AUTOSAR XML (schema 4-3-1)
standard types defined: Double, SInt8, float64, sint8
package /pkg/swc
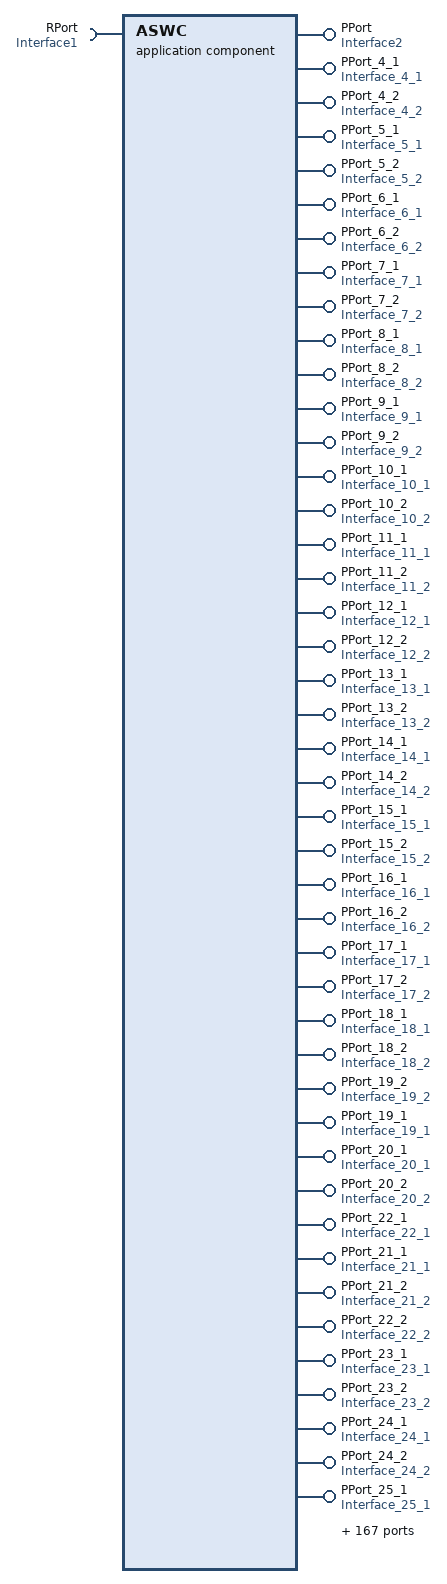
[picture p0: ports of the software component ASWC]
  application sw component type ASWC
    require port RPort: required-interface=Interface1
      required-com-specs:
        {data-element=Interface1/DE1, alive-timeout=60, init-value=constant-reference={short-label=DefaultInitValue_Double, constant=DefaultInitValue_Double}}
        {data-element=Interface1/DE2, alive-timeout=60, init-value=constant-reference={short-label=DefaultInitValu_036fab392deee624, constant=DefaultInitValu_036fab392deee624}}
    211 x provide port:
      PPort: provided-interface=Interface2
        provided-com-specs:
          {data-element=Interface2/DE1, init-value=constant-reference={short-label=DefaultInitValue_SInt8, constant=DefaultInitValue_SInt8}}
          {data-element=Interface2/DE2, init-value=constant-reference={short-label=DefaultInitValue_SInt8, constant=DefaultInitValue_SInt8}}
          {data-element=DE3, init-value=constant-reference={short-label=DefaultInitValu_33c01c7d02936bc6, constant=DefaultInitValu_33c01c7d02936bc6}}
          {data-element=DE4, init-value=constant-reference={short-label=DefaultInitValue_Double, constant=DefaultInitValue_Double}}
      PPort_4_1: nonqueued-sender-com-spec{data-element=DE1, init-value=[0, 0]}, provided-interface=Interface_4_1
      PPort_4_2: nonqueued-sender-com-spec{data-element=DE1, init-value=[0, 0]}, provided-interface=Interface_4_2
      PPort_5_1: nonqueued-sender-com-spec{data-element=DE1, init-value=[0, 0]}, provided-interface=Interface_5_1
      PPort_5_2: nonqueued-sender-com-spec{data-element=DE1, init-value=[0, 0]}, provided-interface=Interface_5_2
      PPort_6_1: nonqueued-sender-com-spec{data-element=DE1, init-value=[0, 0]}, provided-interface=Interface_6_1
      PPort_6_2: nonqueued-sender-com-spec{data-element=DE1, init-value=[0, 0]}, provided-interface=Interface_6_2
      PPort_7_1: nonqueued-sender-com-spec{data-element=DE1, init-value=[0, 0]}, provided-interface=Interface_7_1
      PPort_7_2: nonqueued-sender-com-spec{data-element=DE1, init-value=[0, 0]}, provided-interface=Interface_7_2
      PPort_8_1: nonqueued-sender-com-spec{data-element=DE1, init-value=[0, 0]}, provided-interface=Interface_8_1
      PPort_8_2: nonqueued-sender-com-spec{data-element=DE1, init-value=[0, 0]}, provided-interface=Interface_8_2
      PPort_9_1: nonqueued-sender-com-spec{data-element=DE1, init-value=[0, 0]}, provided-interface=Interface_9_1
      PPort_9_2: nonqueued-sender-com-spec{data-element=DE1, init-value=[0, 0]}, provided-interface=Interface_9_2
      PPort_10_1: nonqueued-sender-com-spec{data-element=DE1, init-value=[0, 0]}, provided-interface=Interface_10_1
      PPort_10_2: nonqueued-sender-com-spec{data-element=DE1, init-value=[0, 0]}, provided-interface=Interface_10_2
      PPort_11_1: nonqueued-sender-com-spec{data-element=DE1, init-value=[0, 0]}, provided-interface=Interface_11_1
      PPort_11_2: nonqueued-sender-com-spec{data-element=DE1, init-value=[0, 0]}, provided-interface=Interface_11_2
      PPort_12_1: nonqueued-sender-com-spec{data-element=DE1, init-value=[0, 0]}, provided-interface=Interface_12_1
      PPort_12_2: nonqueued-sender-com-spec{data-element=DE1, init-value=[0, 0]}, provided-interface=Interface_12_2
      PPort_13_1: nonqueued-sender-com-spec{data-element=DE1, init-value=[0, 0]}, provided-interface=Interface_13_1
      PPort_13_2: nonqueued-sender-com-spec{data-element=DE1, init-value=[0, 0]}, provided-interface=Interface_13_2
      PPort_14_1: nonqueued-sender-com-spec{data-element=DE1, init-value=[0, 0]}, provided-interface=Interface_14_1
      PPort_14_2: nonqueued-sender-com-spec{data-element=DE1, init-value=[0, 0]}, provided-interface=Interface_14_2
      PPort_15_1: nonqueued-sender-com-spec{data-element=DE1, init-value=[0, 0]}, provided-interface=Interface_15_1
      PPort_15_2: nonqueued-sender-com-spec{data-element=DE1, init-value=[0, 0]}, provided-interface=Interface_15_2
      PPort_16_1: nonqueued-sender-com-spec{data-element=DE1, init-value=[0, 0]}, provided-interface=Interface_16_1
      PPort_16_2: nonqueued-sender-com-spec{data-element=DE1, init-value=[0, 0]}, provided-interface=Interface_16_2
      PPort_17_1: nonqueued-sender-com-spec{data-element=DE1, init-value=[0, 0]}, provided-interface=Interface_17_1
      PPort_17_2: nonqueued-sender-com-spec{data-element=DE1, init-value=[0, 0]}, provided-interface=Interface_17_2
      PPort_18_1: nonqueued-sender-com-spec{data-element=DE1, init-value=[0, 0]}, provided-interface=Interface_18_1
      PPort_18_2: nonqueued-sender-com-spec{data-element=DE1, init-value=[0, 0]}, provided-interface=Interface_18_2
      PPort_19_2: nonqueued-sender-com-spec{data-element=DE1, init-value=[0, 0]}, provided-interface=Interface_19_2
      PPort_19_1: nonqueued-sender-com-spec{data-element=DE1, init-value=[0, 0]}, provided-interface=Interface_19_1
      PPort_20_1: nonqueued-sender-com-spec{data-element=DE1, init-value=[0, 0]}, provided-interface=Interface_20_1
      PPort_20_2: nonqueued-sender-com-spec{data-element=DE1, init-value=[0, 0]}, provided-interface=Interface_20_2
      PPort_22_1: nonqueued-sender-com-spec{data-element=DE1, init-value=[0, 0]}, provided-interface=Interface_22_1
      PPort_21_1: nonqueued-sender-com-spec{data-element=DE1, init-value=[0, 0]}, provided-interface=Interface_21_1
      PPort_21_2: nonqueued-sender-com-spec{data-element=DE1, init-value=[0, 0]}, provided-interface=Interface_21_2
      PPort_22_2: nonqueued-sender-com-spec{data-element=DE1, init-value=[0, 0]}, provided-interface=Interface_22_2
      PPort_23_1: nonqueued-sender-com-spec{data-element=DE1, init-value=[0, 0]}, provided-interface=Interface_23_1
      PPort_23_2: nonqueued-sender-com-spec{data-element=DE1, init-value=[0, 0]}, provided-interface=Interface_23_2
      PPort_24_1: nonqueued-sender-com-spec{data-element=DE1, init-value=[0, 0]}, provided-interface=Interface_24_1
      PPort_24_2: nonqueued-sender-com-spec{data-element=DE1, init-value=[0, 0]}, provided-interface=Interface_24_2
      PPort_25_1: nonqueued-sender-com-spec{data-element=DE1, init-value=[0, 0]}, provided-interface=Interface_25_1
      PPort_25_2: nonqueued-sender-com-spec{data-element=DE1, init-value=[0, 0]}, provided-interface=Interface_25_2
      PPort_26_1: nonqueued-sender-com-spec{data-element=DE1, init-value=[0, 0]}, provided-interface=Interface_26_1
      PPort_26_2: nonqueued-sender-com-spec{data-element=DE1, init-value=[0, 0]}, provided-interface=Interface_26_2
      PPort_27_1: nonqueued-sender-com-spec{data-element=DE1, init-value=[0, 0]}, provided-interface=Interface_27_1
      PPort_27_2: nonqueued-sender-com-spec{data-element=DE1, init-value=[0, 0]}, provided-interface=Interface_27_2
      PPort_28_1: nonqueued-sender-com-spec{data-element=DE1, init-value=[0, 0]}, provided-interface=Interface_28_1
      PPort_28_2: nonqueued-sender-com-spec{data-element=DE1, init-value=[0, 0]}, provided-interface=Interface_28_2
      PPort_29_1: nonqueued-sender-com-spec{data-element=DE1, init-value=[0, 0]}, provided-interface=Interface_29_1
      PPort_29_2: nonqueued-sender-com-spec{data-element=DE1, init-value=[0, 0]}, provided-interface=Interface_29_2
      PPort_30_1: nonqueued-sender-com-spec{data-element=DE1, init-value=[0, 0]}, provided-interface=Interface_30_1
      PPort_30_2: nonqueued-sender-com-spec{data-element=DE1, init-value=[0, 0]}, provided-interface=Interface_30_2
      PPort_31_1: nonqueued-sender-com-spec{data-element=DE1, init-value=[0, 0]}, provided-interface=Interface_31_1
      PPort_31_2: nonqueued-sender-com-spec{data-element=DE1, init-value=[0, 0]}, provided-interface=Interface_31_2
      PPort_32_1: nonqueued-sender-com-spec{data-element=DE1, init-value=[0, 0]}, provided-interface=Interface_32_1
      PPort_32_2: nonqueued-sender-com-spec{data-element=DE1, init-value=[0, 0]}, provided-interface=Interface_32_2
      PPort_33_1: nonqueued-sender-com-spec{data-element=DE1, init-value=[0, 0]}, provided-interface=Interface_33_1
      PPort_33_2: nonqueued-sender-com-spec{data-element=DE1, init-value=[0, 0]}, provided-interface=Interface_33_2
      PPort_34_1: nonqueued-sender-com-spec{data-element=DE1, init-value=[0, 0]}, provided-interface=Interface_34_1
      PPort_34_2: nonqueued-sender-com-spec{data-element=DE1, init-value=[0, 0]}, provided-interface=Interface_34_2
      PPort_35_1: nonqueued-sender-com-spec{data-element=DE1, init-value=[0, 0]}, provided-interface=Interface_35_1
      PPort_35_2: nonqueued-sender-com-spec{data-element=DE1, init-value=[0, 0]}, provided-interface=Interface_35_2
      PPort_36_1: nonqueued-sender-com-spec{data-element=DE1, init-value=[0, 0]}, provided-interface=Interface_36_1
      PPort_36_2: nonqueued-sender-com-spec{data-element=DE1, init-value=[0, 0]}, provided-interface=Interface_36_2
      PPort_37_1: nonqueued-sender-com-spec{data-element=DE1, init-value=[0, 0]}, provided-interface=Interface_37_1
      PPort_37_2: nonqueued-sender-com-spec{data-element=DE1, init-value=[0, 0]}, provided-interface=Interface_37_2
      PPort_38_1: nonqueued-sender-com-spec{data-element=DE1, init-value=[0, 0]}, provided-interface=Interface_38_1
      PPort_38_2: nonqueued-sender-com-spec{data-element=DE1, init-value=[0, 0]}, provided-interface=Interface_38_2
      PPort_39_1: nonqueued-sender-com-spec{data-element=DE1, init-value=[0, 0]}, provided-interface=Interface_39_1
      PPort_39_2: nonqueued-sender-com-spec{data-element=DE1, init-value=[0, 0]}, provided-interface=Interface_39_2
      PPort_40_1: nonqueued-sender-com-spec{data-element=DE1, init-value=[0, 0]}, provided-interface=Interface_40_1
      PPort_40_2: nonqueued-sender-com-spec{data-element=DE1, init-value=[0, 0]}, provided-interface=Interface_42_2
      PPort_41_1: nonqueued-sender-com-spec{data-element=DE1, init-value=[0, 0]}, provided-interface=Interface_41_1
      PPort_41_2: nonqueued-sender-com-spec{data-element=DE1, init-value=[0, 0]}, provided-interface=Interface_41_2
      PPort_42_1: nonqueued-sender-com-spec{data-element=DE1, init-value=[0, 0]}, provided-interface=Interface_42_1
      PPort_42_2: nonqueued-sender-com-spec{data-element=DE1, init-value=[0, 0]}, provided-interface=Interface_42_2
      PPort_43_1: nonqueued-sender-com-spec{data-element=DE1, init-value=[0, 0]}, provided-interface=Interface_43_1
      PPort_43_2: nonqueued-sender-com-spec{data-element=DE1, init-value=[0, 0]}, provided-interface=Interface_43_2
      PPort_44_1: nonqueued-sender-com-spec{data-element=DE1, init-value=[0, 0]}, provided-interface=Interface_44_1
      PPort_44_2: nonqueued-sender-com-spec{data-element=DE1, init-value=[0, 0]}, provided-interface=Interface_44_2
      PPort_45_1: nonqueued-sender-com-spec{data-element=DE1, init-value=[0, 0]}, provided-interface=Interface_45_1
      PPort_45_2: nonqueued-sender-com-spec{data-element=DE1, init-value=[0, 0]}, provided-interface=Interface_45_2
      PPort_46_1: nonqueued-sender-com-spec{data-element=DE1, init-value=[0, 0]}, provided-interface=Interface_46_1
      PPort_46_2: nonqueued-sender-com-spec{data-element=DE1, init-value=[0, 0]}, provided-interface=Interface_46_2
      PPort_47_1: nonqueued-sender-com-spec{data-element=DE1, init-value=[0, 0]}, provided-interface=Interface_47_1
      PPort_47_2: nonqueued-sender-com-spec{data-element=DE1, init-value=[0, 0]}, provided-interface=Interface_47_2
      PPort_48_1: nonqueued-sender-com-spec{data-element=DE1, init-value=[0, 0]}, provided-interface=Interface_48_1
      PPort_48_2: nonqueued-sender-com-spec{data-element=DE1, init-value=[0, 0]}, provided-interface=Interface_48_2
      PPort_49_1: nonqueued-sender-com-spec{data-element=DE1, init-value=[0, 0]}, provided-interface=Interface_49_1
      PPort_49_2: nonqueued-sender-com-spec{data-element=DE1, init-value=[0, 0]}, provided-interface=Interface_49_2
      PPort_50_1: nonqueued-sender-com-spec{data-element=DE1, init-value=[0, 0]}, provided-interface=Interface_50_1
      PPort_50_2: nonqueued-sender-com-spec{data-element=DE1, init-value=[0, 0]}, provided-interface=Interface_50_2
      PPort_51_1: nonqueued-sender-com-spec{data-element=DE1, init-value=[0, 0]}, provided-interface=Interface_51_1
      PPort_51_2: nonqueued-sender-com-spec{data-element=DE1, init-value=[0, 0]}, provided-interface=Interface_51_2
      PPort_52_1: nonqueued-sender-com-spec{data-element=DE1, init-value=[0, 0]}, provided-interface=Interface_52_1
      PPort_52_2: nonqueued-sender-com-spec{data-element=DE1, init-value=[0, 0]}, provided-interface=Interface_52_2
      PPort_53_1: nonqueued-sender-com-spec{data-element=DE1, init-value=[0, 0]}, provided-interface=Interface_53_1
      PPort_53_2: nonqueued-sender-com-spec{data-element=DE1, init-value=[0, 0]}, provided-interface=Interface_53_2
      PPort_54_1: nonqueued-sender-com-spec{data-element=DE1, init-value=[0, 0]}, provided-interface=Interface_54_1
      PPort_54_2: nonqueued-sender-com-spec{data-element=DE1, init-value=[0, 0]}, provided-interface=Interface_54_2
      PPort_55_1: nonqueued-sender-com-spec{data-element=DE1, init-value=[0, 0]}, provided-interface=Interface_55_1
      PPort_55_2: nonqueued-sender-com-spec{data-element=DE1, init-value=[0, 0]}, provided-interface=Interface_55_2
      PPort_56_1: nonqueued-sender-com-spec{data-element=DE1, init-value=[0, 0]}, provided-interface=Interface_56_1
      PPort_56_2: nonqueued-sender-com-spec{data-element=DE1, init-value=[0, 0]}, provided-interface=Interface_56_2
      PPort_57_1: nonqueued-sender-com-spec{data-element=DE1, init-value=[0, 0]}, provided-interface=Interface_57_1
      PPort_57_2: nonqueued-sender-com-spec{data-element=DE1, init-value=[0, 0]}, provided-interface=Interface_57_2
      PPort_58_1: nonqueued-sender-com-spec{data-element=DE1, init-value=[0, 0]}, provided-interface=Interface_58_1
      PPort_58_2: nonqueued-sender-com-spec{data-element=DE1, init-value=[0, 0]}, provided-interface=Interface_58_2
      PPort_59_1: nonqueued-sender-com-spec{data-element=DE1, init-value=[0, 0]}, provided-interface=Interface_59_1
      PPort_59_2: nonqueued-sender-com-spec{data-element=DE1, init-value=[0, 0]}, provided-interface=Interface_59_2
      PPort_60_1: nonqueued-sender-com-spec{data-element=DE1, init-value=[0, 0]}, provided-interface=Interface_60_1
      PPort_60_2: nonqueued-sender-com-spec{data-element=DE1, init-value=[0, 0]}, provided-interface=Interface_60_2
      PPort_61_1: nonqueued-sender-com-spec{data-element=DE1, init-value=[0, 0]}, provided-interface=Interface_61_1
      PPort_61_2: nonqueued-sender-com-spec{data-element=DE1, init-value=[0, 0]}, provided-interface=Interface_61_2
      PPort_62_1: nonqueued-sender-com-spec{data-element=DE1, init-value=[0, 0]}, provided-interface=Interface_62_1
      PPort_62_2: nonqueued-sender-com-spec{data-element=DE1, init-value=[0, 0]}, provided-interface=Interface_62_2
      PPort_63_1: nonqueued-sender-com-spec{data-element=DE1, init-value=[0, 0]}, provided-interface=Interface_63_1
      PPort_63_2: nonqueued-sender-com-spec{data-element=DE1, init-value=[0, 0]}, provided-interface=Interface_63_2
      PPort_64_1: nonqueued-sender-com-spec{data-element=DE1, init-value=[0, 0]}, provided-interface=Interface_64_1
      PPort_64_2: nonqueued-sender-com-spec{data-element=DE1, init-value=[0, 0]}, provided-interface=Interface_64_2
      PPort_65_1: nonqueued-sender-com-spec{data-element=DE1, init-value=[0, 0]}, provided-interface=Interface_65_1
      PPort_65_2: nonqueued-sender-com-spec{data-element=DE1, init-value=[0, 0]}, provided-interface=Interface_65_2
      PPort_66_1: nonqueued-sender-com-spec{data-element=DE1, init-value=[0, 0]}, provided-interface=Interface_66_1
      PPort_66_2: nonqueued-sender-com-spec{data-element=DE1, init-value=[0, 0]}, provided-interface=Interface_66_2
      PPort_67_1: nonqueued-sender-com-spec{data-element=DE1, init-value=[0, 0]}, provided-interface=Interface_67_1
      PPort_67_2: nonqueued-sender-com-spec{data-element=DE1, init-value=[0, 0]}, provided-interface=Interface_67_2
      PPort_68_1: nonqueued-sender-com-spec{data-element=DE1, init-value=[0, 0]}, provided-interface=Interface_68_1
      PPort_68_2: nonqueued-sender-com-spec{data-element=DE1, init-value=[0, 0]}, provided-interface=Interface_68_2
      PPort_69_1: nonqueued-sender-com-spec{data-element=DE1, init-value=[0, 0]}, provided-interface=Interface_69_1
      PPort_69_2: nonqueued-sender-com-spec{data-element=DE1, init-value=[0, 0]}, provided-interface=Interface_69_2
      PPort_70_1: nonqueued-sender-com-spec{data-element=DE1, init-value=[0, 0]}, provided-interface=Interface_70_1
      PPort_70_2: nonqueued-sender-com-spec{data-element=DE1, init-value=[0, 0]}, provided-interface=Interface_70_2
      PPort_71_1: nonqueued-sender-com-spec{data-element=DE1, init-value=[0, 0]}, provided-interface=Interface_71_1
      PPort_71_2: nonqueued-sender-com-spec{data-element=DE1, init-value=[0, 0]}, provided-interface=Interface_71_2
      PPort_72_1: nonqueued-sender-com-spec{data-element=DE1, init-value=[0, 0]}, provided-interface=Interface_72_1
      PPort_72_2: nonqueued-sender-com-spec{data-element=DE1, init-value=[0, 0]}, provided-interface=Interface_72_2
      PPort_73_1: nonqueued-sender-com-spec{data-element=DE1, init-value=[0, 0]}, provided-interface=Interface_73_1
      PPort_73_2: nonqueued-sender-com-spec{data-element=DE1, init-value=[0, 0]}, provided-interface=Interface_73_2
      PPort_74_1: nonqueued-sender-com-spec{data-element=DE1, init-value=[0, 0]}, provided-interface=Interface_74_1
      PPort_74_2: nonqueued-sender-com-spec{data-element=DE1, init-value=[0, 0]}, provided-interface=Interface_74_2
      PPort_75_1: nonqueued-sender-com-spec{data-element=DE1, init-value=[0, 0]}, provided-interface=Interface_75_1
      PPort_75_2: nonqueued-sender-com-spec{data-element=DE1, init-value=[0, 0]}, provided-interface=Interface_75_2
      PPort_76_1: nonqueued-sender-com-spec{data-element=DE1, init-value=[0, 0]}, provided-interface=Interface_76_1
      PPort_76_2: nonqueued-sender-com-spec{data-element=DE1, init-value=[0, 0]}, provided-interface=Interface_76_2
      PPort_77_1: nonqueued-sender-com-spec{data-element=DE1, init-value=[0, 0]}, provided-interface=Interface_77_1
      PPort_77_2: nonqueued-sender-com-spec{data-element=DE1, init-value=[0, 0]}, provided-interface=Interface_77_2
      PPort_78_1: nonqueued-sender-com-spec{data-element=DE1, init-value=[0, 0]}, provided-interface=Interface_78_1
      PPort_78_2: nonqueued-sender-com-spec{data-element=DE1, init-value=[0, 0]}, provided-interface=Interface_78_2
      PPort_79_1: nonqueued-sender-com-spec{data-element=DE1, init-value=[0, 0]}, provided-interface=Interface_79_1
      PPort_79_2: nonqueued-sender-com-spec{data-element=DE1, init-value=[0, 0]}, provided-interface=Interface_79_2
      PPort_80_1: nonqueued-sender-com-spec{data-element=DE1, init-value=[0, 0]}, provided-interface=Interface_80_1
      PPort_80_2: nonqueued-sender-com-spec{data-element=DE1, init-value=[0, 0]}, provided-interface=Interface_80_2
      PPort_81_1: nonqueued-sender-com-spec{data-element=DE1, init-value=[0, 0]}, provided-interface=Interface_81_1
      PPort_81_2: nonqueued-sender-com-spec{data-element=DE1, init-value=[0, 0]}, provided-interface=Interface_81_2
      PPort_82_1: nonqueued-sender-com-spec{data-element=DE1, init-value=[0, 0]}, provided-interface=Interface_82_1
      PPort_82_2: nonqueued-sender-com-spec{data-element=DE1, init-value=[0, 0]}, provided-interface=Interface_82_2
      PPort_83_1: nonqueued-sender-com-spec{data-element=DE1, init-value=[0, 0]}, provided-interface=Interface_83_1
      PPort_83_2: nonqueued-sender-com-spec{data-element=DE1, init-value=[0, 0]}, provided-interface=Interface_83_2
      PPort_84_1: nonqueued-sender-com-spec{data-element=DE1, init-value=[0, 0]}, provided-interface=Interface_84_1
      PPort_84_2: nonqueued-sender-com-spec{data-element=DE1, init-value=[0, 0]}, provided-interface=Interface_84_2
      PPort_85_1: nonqueued-sender-com-spec{data-element=DE1, init-value=[0, 0]}, provided-interface=Interface_85_1
      PPort_85_2: nonqueued-sender-com-spec{data-element=DE1, init-value=[0, 0]}, provided-interface=Interface_85_2
      PPort_86_1: nonqueued-sender-com-spec{data-element=DE1, init-value=[0, 0]}, provided-interface=Interface_86_1
      PPort_86_2: nonqueued-sender-com-spec{data-element=DE1, init-value=[0, 0]}, provided-interface=Interface_86_2
      PPort_87_1: nonqueued-sender-com-spec{data-element=DE1, init-value=[0, 0]}, provided-interface=Interface_87_1
      PPort_87_2: nonqueued-sender-com-spec{data-element=DE1, init-value=[0, 0]}, provided-interface=Interface_87_2
      PPort_88_1: nonqueued-sender-com-spec{data-element=DE1, init-value=[0, 0]}, provided-interface=Interface_88_1
      PPort_88_2: nonqueued-sender-com-spec{data-element=DE1, init-value=[0, 0]}, provided-interface=Interface_88_2
      PPort_89_1: nonqueued-sender-com-spec{data-element=DE1, init-value=[0, 0]}, provided-interface=Interface_89_1
      PPort_89_2: nonqueued-sender-com-spec{data-element=DE1, init-value=[0, 0]}, provided-interface=Interface_89_2
      PPort_90_1: nonqueued-sender-com-spec{data-element=DE1, init-value=[0, 0]}, provided-interface=Interface_90_1
      PPort_90_2: nonqueued-sender-com-spec{data-element=DE1, init-value=[0, 0]}, provided-interface=Interface_90_2
      PPort_91_1: nonqueued-sender-com-spec{data-element=DE1, init-value=[0, 0]}, provided-interface=Interface_91_1
      PPort_91_2: nonqueued-sender-com-spec{data-element=DE1, init-value=[0, 0]}, provided-interface=Interface_91_2
      PPort_92_1: nonqueued-sender-com-spec{data-element=DE1, init-value=[0, 0]}, provided-interface=Interface_92_1
      PPort_92_2: nonqueued-sender-com-spec{data-element=DE1, init-value=[0, 0]}, provided-interface=Interface_92_2
      PPort_93_1: nonqueued-sender-com-spec{data-element=DE1, init-value=[0, 0]}, provided-interface=Interface_93_1
      PPort_93_2: nonqueued-sender-com-spec{data-element=DE1, init-value=[0, 0]}, provided-interface=Interface_93_2
      PPort_94_1: nonqueued-sender-com-spec{data-element=DE1, init-value=[0, 0]}, provided-interface=Interface_94_1
      PPort_94_2: nonqueued-sender-com-spec{data-element=DE1, init-value=[0, 0]}, provided-interface=Interface_94_2
      PPort_95_1: nonqueued-sender-com-spec{data-element=DE1, init-value=[0, 0]}, provided-interface=Interface_95_1
      PPort_95_2: nonqueued-sender-com-spec{data-element=DE1, init-value=[0, 0]}, provided-interface=Interface_95_2
      PPort_96_1: nonqueued-sender-com-spec{data-element=DE1, init-value=[0, 0]}, provided-interface=Interface_96_1
      PPort_96_2: nonqueued-sender-com-spec{data-element=DE1, init-value=[0, 0]}, provided-interface=Interface_96_2
      PPort_97_1: nonqueued-sender-com-spec{data-element=DE1, init-value=[0, 0]}, provided-interface=Interface_97_1
      PPort_97_2: nonqueued-sender-com-spec{data-element=DE1, init-value=[0, 0]}, provided-interface=Interface_97_2
      PPort_98_1: nonqueued-sender-com-spec{data-element=DE1, init-value=[0, 0]}, provided-interface=Interface_98_1
      PPort_98_2: nonqueued-sender-com-spec{data-element=DE1, init-value=[0, 0]}, provided-interface=Interface_98_2
      PPort_99_1: nonqueued-sender-com-spec{data-element=DE1, init-value=[0, 0]}, provided-interface=Interface_99_1
      PPort_99_2: nonqueued-sender-com-spec{data-element=DE1, init-value=[0, 0]}, provided-interface=Interface_99_2
      PPort_100_1: nonqueued-sender-com-spec{data-element=DE1, init-value=[0, 0]}, provided-interface=Interface_100_1
      PPort_100_2: nonqueued-sender-com-spec{data-element=DE1, init-value=[0, 0]}, provided-interface=Interface_100_2
      PPort_101_1: nonqueued-sender-com-spec{data-element=DE1, init-value=[0, 0]}, provided-interface=Interface_101_1
      PPort_101_2: nonqueued-sender-com-spec{data-element=DE1, init-value=[0, 0]}, provided-interface=Interface_101_2
      PPort_102_1: nonqueued-sender-com-spec{data-element=DE1, init-value=[0, 0]}, provided-interface=Interface_102_1
      PPort_102_2: nonqueued-sender-com-spec{data-element=DE1, init-value=[0, 0]}, provided-interface=Interface_102_2
      PPort_103_1: nonqueued-sender-com-spec{data-element=DE1, init-value=[0, 0]}, provided-interface=Interface_103_1
      PPort_103_2: nonqueued-sender-com-spec{data-element=DE1, init-value=[0, 0]}, provided-interface=Interface_103_2
      PPort_104_1: nonqueued-sender-com-spec{data-element=DE1, init-value=[0, 0]}, provided-interface=Interface_104_1
      PPort_104_2: nonqueued-sender-com-spec{data-element=DE1, init-value=[0, 0]}, provided-interface=Interface_104_2
      PPort_105_1: nonqueued-sender-com-spec{data-element=DE1, init-value=[0, 0]}, provided-interface=Interface_105_1
      PPort_105_2: nonqueued-sender-com-spec{data-element=DE1, init-value=[0, 0]}, provided-interface=Interface_105_2
      PPort_106_1: nonqueued-sender-com-spec{data-element=DE1, init-value=[0, 0]}, provided-interface=Interface_106_1
      PPort_106_2: nonqueued-sender-com-spec{data-element=DE1, init-value=[0, 0]}, provided-interface=Interface_106_2
      PPort_107_1: nonqueued-sender-com-spec{data-element=DE1, init-value=[0, 0]}, provided-interface=Interface_107_1
      PPort_107_2: nonqueued-sender-com-spec{data-element=DE1, init-value=[0, 0]}, provided-interface=Interface_107_2
      PPort_108_1: nonqueued-sender-com-spec{data-element=DE1, init-value=[0, 0]}, provided-interface=Interface_108_1
      PPort_108_2: nonqueued-sender-com-spec{data-element=DE1, init-value=[0, 0]}, provided-interface=Interface_108_2
    behavior IB: handle-termination-and-restart=NO-SUPPORT
      108 x timing event:
        Event_t_1tic_A: start-on-event=Runnable1, period=1
        Event_t_1tic_B: start-on-event=Runnable2, period=1
        Event_t_10tic: start-on-event=Runnable3, period=10
        Event_{4..103}: start-on-event=Runnable{4..103}, period=1
        Event104: start-on-event=Runnable104, period=1
        Event_{105..108}: start-on-event=Runnable{105..108}, period=1
      implicit-inter-runnable-variables:
        109 x data, all with sw-calibration-access=READ-ONLY:
          IRV1: category=VALUE, type=Double, init-value=constant-reference={short-label=DefaultInitValue_Double, constant=DefaultInitValue_Double}
          IRV2: category=VALUE, type=Double, init-value=constant-reference={short-label=DefaultInitValue_Double, constant=DefaultInitValue_Double}
          IRV3: category=VALUE, type=SInt8, init-value=constant-reference={short-label=DefaultInitValue_SInt8, constant=DefaultInitValue_SInt8}
          IRV4: category=VALUE, type=Double, init-value=constant-reference={short-label=DefaultInitValue_Double, constant=DefaultInitValue_Double}
          IRV108: category=ARRAY, type=rt_Array_SInt8_2, init-value=[0, 0]
          IRV107: category=ARRAY, type=rt_Array_SInt8_2, init-value=[0, 0]
          IRV106: category=ARRAY, type=rt_Array_SInt8_2, init-value=[0, 0]
          IRV105: category=ARRAY, type=rt_Array_SInt8_2, init-value=[0, 0]
          IRV104: category=ARRAY, type=rt_Array_SInt8_2, init-value=[0, 0]
          IRV103: category=ARRAY, type=rt_Array_SInt8_2, init-value=[0, 0]
          IRV102: category=ARRAY, type=rt_Array_SInt8_2, init-value=[0, 0]
          IRV101: category=ARRAY, type=rt_Array_SInt8_2, init-value=[0, 0]
          IRV100: category=ARRAY, type=rt_Array_SInt8_2, init-value=[0, 0]
          IRV99: category=ARRAY, type=rt_Array_SInt8_2, init-value=[0, 0]
          IRV98: category=ARRAY, type=rt_Array_SInt8_2, init-value=[0, 0]
          IRV97: category=ARRAY, type=rt_Array_SInt8_2, init-value=[0, 0]
          IRV96: category=ARRAY, type=rt_Array_SInt8_2, init-value=[0, 0]
          IRV95: category=ARRAY, type=rt_Array_SInt8_2, init-value=[0, 0]
          IRV94: category=ARRAY, type=rt_Array_SInt8_2, init-value=[0, 0]
          IRV93: category=ARRAY, type=rt_Array_SInt8_2, init-value=[0, 0]
          IRV92: category=ARRAY, type=rt_Array_SInt8_2, init-value=[0, 0]
          IRV91: category=ARRAY, type=rt_Array_SInt8_2, init-value=[0, 0]
          IRV90: category=ARRAY, type=rt_Array_SInt8_2, init-value=[0, 0]
          IRV89: category=ARRAY, type=rt_Array_SInt8_2, init-value=[0, 0]
          IRV88: category=ARRAY, type=rt_Array_SInt8_2, init-value=[0, 0]
          IRV87: category=ARRAY, type=rt_Array_SInt8_2, init-value=[0, 0]
          IRV86: category=ARRAY, type=rt_Array_SInt8_2, init-value=[0, 0]
          IRV85: category=ARRAY, type=rt_Array_SInt8_2, init-value=[0, 0]
          IRV84: category=ARRAY, type=rt_Array_SInt8_2, init-value=[0, 0]
          IRV83: category=ARRAY, type=rt_Array_SInt8_2, init-value=[0, 0]
          IRV82: category=ARRAY, type=rt_Array_SInt8_2, init-value=[0, 0]
          IRV81: category=ARRAY, type=rt_Array_SInt8_2, init-value=[0, 0]
          IRV80: category=ARRAY, type=rt_Array_SInt8_2, init-value=[0, 0]
          IRV79: category=ARRAY, type=rt_Array_SInt8_2, init-value=[0, 0]
          IRV78: category=ARRAY, type=rt_Array_SInt8_2, init-value=[0, 0]
          IRV77: category=ARRAY, type=rt_Array_SInt8_2, init-value=[0, 0]
          IRV76: category=ARRAY, type=rt_Array_SInt8_2, init-value=[0, 0]
          IRV75: category=ARRAY, type=rt_Array_SInt8_2, init-value=[0, 0]
          IRV74: category=ARRAY, type=rt_Array_SInt8_2, init-value=[0, 0]
          IRV73: category=ARRAY, type=rt_Array_SInt8_2, init-value=[0, 0]
          IRV72: category=ARRAY, type=rt_Array_SInt8_2, init-value=[0, 0]
          IRV71: category=ARRAY, type=rt_Array_SInt8_2, init-value=[0, 0]
          IRV70: category=ARRAY, type=rt_Array_SInt8_2, init-value=[0, 0]
          IRV69: category=ARRAY, type=rt_Array_SInt8_2, init-value=[0, 0]
          IRV68: category=ARRAY, type=rt_Array_SInt8_2, init-value=[0, 0]
          IRV67: category=ARRAY, type=rt_Array_SInt8_2, init-value=[0, 0]
          IRV66: category=ARRAY, type=rt_Array_SInt8_2, init-value=[0, 0]
          IRV65: category=ARRAY, type=rt_Array_SInt8_2, init-value=[0, 0]
          IRV64: category=ARRAY, type=rt_Array_SInt8_2, init-value=[0, 0]
          IRV63: category=ARRAY, type=rt_Array_SInt8_2, init-value=[0, 0]
          IRV62: category=ARRAY, type=rt_Array_SInt8_2, init-value=[0, 0]
          IRV61: category=ARRAY, type=rt_Array_SInt8_2, init-value=[0, 0]
          IRV60: category=ARRAY, type=rt_Array_SInt8_2, init-value=[0, 0]
          IRV59: category=ARRAY, type=rt_Array_SInt8_2, init-value=[0, 0]
          IRV58: category=ARRAY, type=rt_Array_SInt8_2, init-value=[0, 0]
          IRV57: category=ARRAY, type=rt_Array_SInt8_2, init-value=[0, 0]
          IRV56: category=ARRAY, type=rt_Array_SInt8_2, init-value=[0, 0]
          IRV55: category=ARRAY, type=rt_Array_SInt8_2, init-value=[0, 0]
          IRV54: category=ARRAY, type=rt_Array_SInt8_2, init-value=[0, 0]
          IRV53: category=ARRAY, type=rt_Array_SInt8_2, init-value=[0, 0]
          IRV52: category=ARRAY, type=rt_Array_SInt8_2, init-value=[0, 0]
          IRV51: category=ARRAY, type=rt_Array_SInt8_2, init-value=[0, 0]
          IRV50: category=ARRAY, type=rt_Array_SInt8_2, init-value=[0, 0]
          IRV49: category=ARRAY, type=rt_Array_SInt8_2, init-value=[0, 0]
          IRV48: category=ARRAY, type=rt_Array_SInt8_2, init-value=[0, 0]
          IRV47: category=ARRAY, type=rt_Array_SInt8_2, init-value=[0, 0]
          IRV46: category=ARRAY, type=rt_Array_SInt8_2, init-value=[0, 0]
          IRV45: category=ARRAY, type=rt_Array_SInt8_2, init-value=[0, 0]
          IRV44: category=ARRAY, type=rt_Array_SInt8_2, init-value=[0, 0]
          IRV43: category=ARRAY, type=rt_Array_SInt8_2, init-value=[0, 0]
          IRV42: category=ARRAY, type=rt_Array_SInt8_2, init-value=[0, 0]
          IRV41: category=ARRAY, type=rt_Array_SInt8_2, init-value=[0, 0]
          IRV40: category=ARRAY, type=rt_Array_SInt8_2, init-value=[0, 0]
          IRV39: category=ARRAY, type=rt_Array_SInt8_2, init-value=[0, 0]
          IRV38: category=ARRAY, type=rt_Array_SInt8_2, init-value=[0, 0]
          IRV37: category=ARRAY, type=rt_Array_SInt8_2, init-value=[0, 0]
          IRV36: category=ARRAY, type=rt_Array_SInt8_2, init-value=[0, 0]
          IRV35: category=ARRAY, type=rt_Array_SInt8_2, init-value=[0, 0]
          IRV34: category=ARRAY, type=rt_Array_SInt8_2, init-value=[0, 0]
          IRV33: category=ARRAY, type=rt_Array_SInt8_2, init-value=[0, 0]
          IRV32: category=ARRAY, type=rt_Array_SInt8_2, init-value=[0, 0]
          IRV31: category=ARRAY, type=rt_Array_SInt8_2, init-value=[0, 0]
          IRV30: category=ARRAY, type=rt_Array_SInt8_2, init-value=[0, 0]
          IRV29: category=ARRAY, type=rt_Array_SInt8_2, init-value=[0, 0]
          IRV28: category=ARRAY, type=rt_Array_SInt8_2, init-value=[0, 0]
          IRV27: category=ARRAY, type=rt_Array_SInt8_2, init-value=[0, 0]
          IRV26: category=ARRAY, type=rt_Array_SInt8_2, init-value=[0, 0]
          IRV25: category=ARRAY, type=rt_Array_SInt8_2, init-value=[0, 0]
          IRV24: category=ARRAY, type=rt_Array_SInt8_2, init-value=[0, 0]
          IRV23: category=ARRAY, type=rt_Array_SInt8_2, init-value=[0, 0]
          IRV22: category=ARRAY, type=rt_Array_SInt8_2, init-value=[0, 0]
          IRV21: category=ARRAY, type=rt_Array_SInt8_2, init-value=[0, 0]
          IRV20: category=ARRAY, type=rt_Array_SInt8_2, init-value=[0, 0]
          IRV19: category=ARRAY, type=rt_Array_SInt8_2, init-value=[0, 0]
          IRV18: category=ARRAY, type=rt_Array_SInt8_2, init-value=[0, 0]
          IRV17: category=ARRAY, type=rt_Array_SInt8_2, init-value=[0, 0]
          IRV16: category=ARRAY, type=rt_Array_SInt8_2, init-value=[0, 0]
          IRV15: category=ARRAY, type=rt_Array_SInt8_2, init-value=[0, 0]
          IRV14: category=ARRAY, type=rt_Array_SInt8_2, init-value=[0, 0]
          IRV13: category=ARRAY, type=rt_Array_SInt8_2, init-value=[0, 0]
          IRV12: category=ARRAY, type=rt_Array_SInt8_2, init-value=[0, 0]
          IRV11: category=ARRAY, type=rt_Array_SInt8_2, init-value=[0, 0]
          IRV10: category=ARRAY, type=rt_Array_SInt8_2, init-value=[0, 0]
          IRV9: category=ARRAY, type=rt_Array_SInt8_2, init-value=[0, 0]
          IRV8: category=ARRAY, type=rt_Array_SInt8_2, init-value=[0, 0]
          IRV7: category=ARRAY, type=rt_Array_SInt8_2, init-value=[0, 0]
          IRV6: category=ARRAY, type=rt_Array_SInt8_2, init-value=[0, 0]
          IRV5: category=ARRAY, type=rt_Array_SInt8_2, init-value=[0, 0]
          IRV109: category=ARRAY, type=rt_Array_SInt8_2, init-value=[0, 0]
      109 x runnable:
        Runnable_Init
        Runnable1
          data-read-access:
            access IN_RPort_DE1: accessed-variable=RPort.DE1
          data-write-access:
            access OUT_PPort_DE1: accessed-variable=PPort.DE1
          read-local-variables:
            access RV_IRV3: accessed-variable=IRV3
          written-local-variables:
            access WV_IRV1: accessed-variable=IRV1
        Runnable104
          data-write-access:
            access OUT_PPort_104_1_DE1: accessed-variable=PPort_104_1.DE1
            access OUT_PPort_104_2_DE1: accessed-variable=PPort_104_2.DE1
          read-local-variables:
            access RV_IRV105: accessed-variable=IRV105
          written-local-variables:
            access WV_IRV106: accessed-variable=IRV106
        Runnable105
          data-write-access:
            access OUT_PPort_105_1_DE1: accessed-variable=PPort_105_1.DE1
            access OUT_PPort_105_2_DE1: accessed-variable=PPort_105_2.DE1
          read-local-variables:
            access RV_IRV106: accessed-variable=IRV106
          written-local-variables:
            access WV_IRV107: accessed-variable=IRV107
        Runnable106
          data-write-access:
            access OUT_PPort_106_1_DE1: accessed-variable=PPort_106_1.DE1
            access OUT_PPort_106_2_DE1: accessed-variable=PPort_106_2.DE1
          read-local-variables:
            access RV_IRV107: accessed-variable=IRV107
          written-local-variables:
            access WV_IRV108: accessed-variable=IRV108
        Runnable107
          data-write-access:
            access OUT_PPort_107_1_DE1: accessed-variable=PPort_107_1.DE1
            access OUT_PPort_107_2_DE1: accessed-variable=PPort_107_2.DE1
          read-local-variables:
            access RV_IRV108: accessed-variable=IRV108
          written-local-variables:
            access WV_IRV109: accessed-variable=IRV109
        Runnable108
          data-write-access:
            access OUT_PPort_108_1_DE1: accessed-variable=PPort_108_1.DE1
            access OUT_PPort_108_2_DE1: accessed-variable=PPort_108_2.DE1
          read-local-variables:
            access RV_IRV109: accessed-variable=IRV109
        Runnable2
          data-write-access:
            access OUT_PPort_DE3: accessed-variable=PPort.DE3
            access OUT_PPort_DE4: accessed-variable=PPort.DE4
          read-local-variables:
            access RV_IRV1: accessed-variable=IRV1
            access RV_IRV2: accessed-variable=IRV2
          written-local-variables:
            access WV_IRV4: accessed-variable=IRV4
            access WV_IRV5: accessed-variable=IRV5
        Runnable3
          data-read-access:
            access IN_RPort_DE2: accessed-variable=RPort.DE2
          data-write-access:
            access OUT_PPort_DE2: accessed-variable=PPort.DE2
          read-local-variables:
            access RV_IRV4: accessed-variable=IRV4
          written-local-variables:
            access WV_IRV2: accessed-variable=IRV2
            access WV_IRV3: accessed-variable=IRV3
        Runnable4
          data-write-access:
            access OUT_PPort_4_1_DE1: accessed-variable=PPort_4_1.DE1
            access OUT_PPort_4_2_DE1: accessed-variable=PPort_4_2.DE1
          read-local-variables:
            access RV_IRV5: accessed-variable=IRV5
          written-local-variables:
            access WV_IRV6: accessed-variable=IRV6
        Runnable103
          data-write-access:
            access OUT_PPort_103_1_DE1: accessed-variable=PPort_103_1.DE1
            access OUT_PPort_103_2_DE1: accessed-variable=PPort_103_2.DE1
          read-local-variables:
            access RV_IRV104: accessed-variable=IRV104
          written-local-variables:
            access WV_IRV105: accessed-variable=IRV105
        Runnable102
          data-write-access:
            access OUT_PPort_102_1_DE1: accessed-variable=PPort_102_1.DE1
            access OUT_PPort_102_2_DE1: accessed-variable=PPort_102_2.DE1
          read-local-variables:
            access RV_IRV103: accessed-variable=IRV103
          written-local-variables:
            access WV_IRV104: accessed-variable=IRV104
        Runnable101
          data-write-access:
            access OUT_PPort_101_1_DE1: accessed-variable=PPort_101_1.DE1
            access OUT_PPort_101_2_DE1: accessed-variable=PPort_101_2.DE1
          read-local-variables:
            access RV_IRV102: accessed-variable=IRV102
          written-local-variables:
            access WV_IRV103: accessed-variable=IRV103
        Runnable100
          data-write-access:
            access OUT_PPort_100_1_DE1: accessed-variable=PPort_100_1.DE1
            access OUT_PPort_100_2_DE1: accessed-variable=PPort_100_2.DE1
          read-local-variables:
            access RV_IRV101: accessed-variable=IRV101
          written-local-variables:
            access WV_IRV102: accessed-variable=IRV102
        Runnable99
          data-write-access:
            access OUT_PPort_99_1_DE1: accessed-variable=PPort_99_1.DE1
            access OUT_PPort_99_2_DE1: accessed-variable=PPort_99_2.DE1
          read-local-variables:
            access RV_IRV100: accessed-variable=IRV100
          written-local-variables:
            access WV_IRV101: accessed-variable=IRV101
        Runnable98
          data-write-access:
            access OUT_PPort_98_1_DE1: accessed-variable=PPort_98_1.DE1
            access OUT_PPort_98_2_DE1: accessed-variable=PPort_98_2.DE1
          read-local-variables:
            access RV_IRV99: accessed-variable=IRV99
          written-local-variables:
            access WV_IRV100: accessed-variable=IRV100
        Runnable97
          data-write-access:
            access OUT_PPort_97_1_DE1: accessed-variable=PPort_97_1.DE1
            access OUT_PPort_97_2_DE1: accessed-variable=PPort_97_2.DE1
          read-local-variables:
            access RV_IRV98: accessed-variable=IRV98
          written-local-variables:
            access WV_IRV99: accessed-variable=IRV99
        Runnable96
          data-write-access:
            access OUT_PPort_96_1_DE1: accessed-variable=PPort_96_1.DE1
            access OUT_PPort_96_2_DE1: accessed-variable=PPort_96_2.DE1
          read-local-variables:
            access RV_IRV97: accessed-variable=IRV97
          written-local-variables:
            access WV_IRV98: accessed-variable=IRV98
        Runnable95
          data-write-access:
            access OUT_PPort_95_1_DE1: accessed-variable=PPort_95_1.DE1
            access OUT_PPort_95_2_DE1: accessed-variable=PPort_95_2.DE1
          read-local-variables:
            access RV_IRV96: accessed-variable=IRV96
          written-local-variables:
            access WV_IRV97: accessed-variable=IRV97
        Runnable94
          data-write-access:
            access OUT_PPort_94_1_DE1: accessed-variable=PPort_94_1.DE1
            access OUT_PPort_94_2_DE1: accessed-variable=PPort_94_2.DE1
          read-local-variables:
            access RV_IRV95: accessed-variable=IRV95
          written-local-variables:
            access WV_IRV96: accessed-variable=IRV96
        Runnable93
          data-write-access:
            access OUT_PPort_93_1_DE1: accessed-variable=PPort_93_1.DE1
            access OUT_PPort_93_2_DE1: accessed-variable=PPort_93_2.DE1
          read-local-variables:
            access RV_IRV94: accessed-variable=IRV94
          written-local-variables:
            access WV_IRV95: accessed-variable=IRV95
        Runnable92
          data-write-access:
            access OUT_PPort_92_1_DE1: accessed-variable=PPort_92_1.DE1
            access OUT_PPort_92_2_DE1: accessed-variable=PPort_92_2.DE1
          read-local-variables:
            access RV_IRV93: accessed-variable=IRV93
          written-local-variables:
            access WV_IRV94: accessed-variable=IRV94
        Runnable91
          data-write-access:
            access OUT_PPort_91_1_DE1: accessed-variable=PPort_91_1.DE1
            access OUT_PPort_91_2_DE1: accessed-variable=PPort_91_2.DE1
          read-local-variables:
            access RV_IRV92: accessed-variable=IRV92
          written-local-variables:
            access WV_IRV93: accessed-variable=IRV93
        Runnable90
          data-write-access:
            access OUT_PPort_90_1_DE1: accessed-variable=PPort_90_1.DE1
            access OUT_PPort_90_2_DE1: accessed-variable=PPort_90_2.DE1
          read-local-variables:
            access RV_IRV91: accessed-variable=IRV91
          written-local-variables:
            access WV_IRV92: accessed-variable=IRV92
        Runnable89
          data-write-access:
            access OUT_PPort_89_1_DE1: accessed-variable=PPort_89_1.DE1
            access OUT_PPort_89_2_DE1: accessed-variable=PPort_89_2.DE1
          read-local-variables:
            access RV_IRV90: accessed-variable=IRV90
          written-local-variables:
            access WV_IRV91: accessed-variable=IRV91
        Runnable88
          data-write-access:
            access OUT_PPort_88_1_DE1: accessed-variable=PPort_88_1.DE1
            access OUT_PPort_88_2_DE1: accessed-variable=PPort_88_2.DE1
          read-local-variables:
            access RV_IRV89: accessed-variable=IRV89
          written-local-variables:
            access WV_IRV90: accessed-variable=IRV90
        Runnable87
          data-write-access:
            access OUT_PPort_87_1_DE1: accessed-variable=PPort_87_1.DE1
            access OUT_PPort_87_2_DE1: accessed-variable=PPort_87_2.DE1
          read-local-variables:
            access RV_IRV88: accessed-variable=IRV88
          written-local-variables:
            access WV_IRV89: accessed-variable=IRV89
        Runnable85
          data-write-access:
            access OUT_PPort_85_1_DE1: accessed-variable=PPort_85_1.DE1
            access OUT_PPort_85_2_DE1: accessed-variable=PPort_85_2.DE1
          read-local-variables:
            access RV_IRV86: accessed-variable=IRV86
          written-local-variables:
            access WV_IRV87: accessed-variable=IRV87
        Runnable84
          data-write-access:
            access OUT_PPort_84_1_DE1: accessed-variable=PPort_84_1.DE1
            access OUT_PPort_84_2_DE1: accessed-variable=PPort_84_2.DE1
          read-local-variables:
            access RV_IRV85: accessed-variable=IRV85
          written-local-variables:
            access WV_IRV86: accessed-variable=IRV86
        Runnable83
          data-write-access:
            access OUT_PPort_83_1_DE1: accessed-variable=PPort_83_1.DE1
            access OUT_PPort_83_2_DE1: accessed-variable=PPort_83_2.DE1
          read-local-variables:
            access RV_IRV84: accessed-variable=IRV84
          written-local-variables:
            access WV_IRV85: accessed-variable=IRV85
        Runnable82
          data-write-access:
            access OUT_PPort_82_1_DE1: accessed-variable=PPort_82_1.DE1
            access OUT_PPort_82_2_DE1: accessed-variable=PPort_82_2.DE1
          read-local-variables:
            access RV_IRV83: accessed-variable=IRV83
          written-local-variables:
            access WV_IRV84: accessed-variable=IRV84
        Runnable81
          data-write-access:
            access OUT_PPort_81_1_DE1: accessed-variable=PPort_81_1.DE1
            access OUT_PPort_81_2_DE1: accessed-variable=PPort_81_2.DE1
          read-local-variables:
            access RV_IRV82: accessed-variable=IRV82
          written-local-variables:
            access WV_IRV83: accessed-variable=IRV83
        Runnable80
          data-write-access:
            access OUT_PPort_80_1_DE1: accessed-variable=PPort_80_1.DE1
            access OUT_PPort_80_2_DE1: accessed-variable=PPort_80_2.DE1
          read-local-variables:
            access RV_IRV81: accessed-variable=IRV81
          written-local-variables:
            access WV_IRV82: accessed-variable=IRV82
        Runnable79
          data-write-access:
            access OUT_PPort_79_1_DE1: accessed-variable=PPort_79_1.DE1
            access OUT_PPort_79_2_DE1: accessed-variable=PPort_79_2.DE1
          read-local-variables:
            access RV_IRV80: accessed-variable=IRV80
          written-local-variables:
            access WV_IRV81: accessed-variable=IRV81
        Runnable78
          data-write-access:
            access OUT_PPort_78_1_DE1: accessed-variable=PPort_78_1.DE1
            access OUT_PPort_78_2_DE1: accessed-variable=PPort_78_2.DE1
          read-local-variables:
            access RV_IRV79: accessed-variable=IRV79
          written-local-variables:
            access WV_IRV80: accessed-variable=IRV80
        Runnable77
          data-write-access:
            access OUT_PPort_77_1_DE1: accessed-variable=PPort_77_1.DE1
            access OUT_PPort_77_2_DE1: accessed-variable=PPort_77_2.DE1
          read-local-variables:
            access RV_IRV78: accessed-variable=IRV78
          written-local-variables:
            access WV_IRV79: accessed-variable=IRV79
        Runnable76
          data-write-access:
            access OUT_PPort_76_1_DE1: accessed-variable=PPort_76_1.DE1
            access OUT_PPort_76_2_DE1: accessed-variable=PPort_76_2.DE1
          read-local-variables:
            access RV_IRV77: accessed-variable=IRV77
          written-local-variables:
            access WV_IRV78: accessed-variable=IRV78
        Runnable75
          data-write-access:
            access OUT_PPort_75_1_DE1: accessed-variable=PPort_75_1.DE1
            access OUT_PPort_75_2_DE1: accessed-variable=PPort_75_2.DE1
          read-local-variables:
            access RV_IRV76: accessed-variable=IRV76
          written-local-variables:
            access WV_IRV77: accessed-variable=IRV77
        Runnable74
          data-write-access:
            access OUT_PPort_74_1_DE1: accessed-variable=PPort_74_1.DE1
            access OUT_PPort_74_2_DE1: accessed-variable=PPort_74_2.DE1
          read-local-variables:
            access RV_IRV75: accessed-variable=IRV75
          written-local-variables:
            access WV_IRV76: accessed-variable=IRV76
        Runnable73
          data-write-access:
            access OUT_PPort_73_1_DE1: accessed-variable=PPort_73_1.DE1
            access OUT_PPort_73_2_DE1: accessed-variable=PPort_73_2.DE1
          read-local-variables:
            access RV_IRV74: accessed-variable=IRV74
          written-local-variables:
            access WV_IRV75: accessed-variable=IRV75
        Runnable72
          data-write-access:
            access OUT_PPort_72_1_DE1: accessed-variable=PPort_72_1.DE1
            access OUT_PPort_72_2_DE1: accessed-variable=PPort_72_2.DE1
          read-local-variables:
            access RV_IRV73: accessed-variable=IRV73
          written-local-variables:
            access WV_IRV74: accessed-variable=IRV74
        Runnable71
          data-write-access:
            access OUT_PPort_71_1_DE1: accessed-variable=PPort_71_1.DE1
            access OUT_PPort_71_2_DE1: accessed-variable=PPort_71_2.DE1
          read-local-variables:
            access RV_IRV72: accessed-variable=IRV72
          written-local-variables:
            access WV_IRV73: accessed-variable=IRV73
        Runnable69
          data-write-access:
            access OUT_PPort_69_1_DE1: accessed-variable=PPort_69_1.DE1
            access OUT_PPort_69_2_DE1: accessed-variable=PPort_69_2.DE1
          read-local-variables:
            access RV_IRV70: accessed-variable=IRV70
          written-local-variables:
            access WV_IRV71: accessed-variable=IRV71
        Runnable68
          data-write-access:
            access OUT_PPort_68_1_DE1: accessed-variable=PPort_68_1.DE1
            access OUT_PPort_68_2_DE1: accessed-variable=PPort_68_2.DE1
          read-local-variables:
            access RV_IRV69: accessed-variable=IRV69
          written-local-variables:
            access WV_IRV70: accessed-variable=IRV70
        Runnable67
          data-write-access:
            access OUT_PPort_67_1_DE1: accessed-variable=PPort_67_1.DE1
            access OUT_PPort_67_2_DE1: accessed-variable=PPort_67_2.DE1
          read-local-variables:
            access RV_IRV68: accessed-variable=IRV68
          written-local-variables:
            access WV_IRV69: accessed-variable=IRV69
        Runnable66
          data-write-access:
            access OUT_PPort_66_1_DE1: accessed-variable=PPort_66_1.DE1
            access OUT_PPort_66_2_DE1: accessed-variable=PPort_66_2.DE1
          read-local-variables:
            access RV_IRV67: accessed-variable=IRV67
          written-local-variables:
            access WV_IRV68: accessed-variable=IRV68
        Runnable65
          data-write-access:
            access OUT_PPort_65_1_DE1: accessed-variable=PPort_65_1.DE1
            access OUT_PPort_65_2_DE1: accessed-variable=PPort_65_2.DE1
          read-local-variables:
            access RV_IRV66: accessed-variable=IRV66
          written-local-variables:
            access WV_IRV67: accessed-variable=IRV67
        Runnable64
          data-write-access:
            access OUT_PPort_64_1_DE1: accessed-variable=PPort_64_1.DE1
            access OUT_PPort_64_2_DE1: accessed-variable=PPort_64_2.DE1
          read-local-variables:
            access RV_IRV65: accessed-variable=IRV65
          written-local-variables:
            access WV_IRV66: accessed-variable=IRV66
        Runnable63
          data-write-access:
            access OUT_PPort_63_1_DE1: accessed-variable=PPort_63_1.DE1
            access OUT_PPort_63_2_DE1: accessed-variable=PPort_63_2.DE1
          read-local-variables:
            access RV_IRV64: accessed-variable=IRV64
          written-local-variables:
            access WV_IRV65: accessed-variable=IRV65
        Runnable62
          data-write-access:
            access OUT_PPort_62_1_DE1: accessed-variable=PPort_62_1.DE1
            access OUT_PPort_62_2_DE1: accessed-variable=PPort_62_2.DE1
          read-local-variables:
            access RV_IRV63: accessed-variable=IRV63
          written-local-variables:
            access WV_IRV64: accessed-variable=IRV64
        Runnable61
          data-write-access:
            access OUT_PPort_61_1_DE1: accessed-variable=PPort_61_1.DE1
            access OUT_PPort_61_2_DE1: accessed-variable=PPort_61_2.DE1
          read-local-variables:
            access RV_IRV62: accessed-variable=IRV62
          written-local-variables:
            access WV_IRV63: accessed-variable=IRV63
        Runnable60
          data-write-access:
            access OUT_PPort_60_1_DE1: accessed-variable=PPort_60_1.DE1
            access OUT_PPort_60_2_DE1: accessed-variable=PPort_60_2.DE1
          read-local-variables:
            access RV_IRV61: accessed-variable=IRV61
          written-local-variables:
            access WV_IRV62: accessed-variable=IRV62
        Runnable59
          data-write-access:
            access OUT_PPort_59_1_DE1: accessed-variable=PPort_59_1.DE1
            access OUT_PPort_59_2_DE1: accessed-variable=PPort_59_2.DE1
          read-local-variables:
            access RV_IRV60: accessed-variable=IRV60
          written-local-variables:
            access WV_IRV61: accessed-variable=IRV61
        Runnable58
          data-write-access:
            access OUT_PPort_58_1_DE1: accessed-variable=PPort_58_1.DE1
            access OUT_PPort_58_2_DE1: accessed-variable=PPort_58_2.DE1
          read-local-variables:
            access RV_IRV59: accessed-variable=IRV59
          written-local-variables:
            access WV_IRV60: accessed-variable=IRV60
        Runnable57
          data-write-access:
            access OUT_PPort_57_1_DE1: accessed-variable=PPort_57_1.DE1
            access OUT_PPort_57_2_DE1: accessed-variable=PPort_57_2.DE1
          read-local-variables:
            access RV_IRV58: accessed-variable=IRV58
          written-local-variables:
            access WV_IRV59: accessed-variable=IRV59
        Runnable54
          data-write-access:
            access OUT_PPort_54_1_DE1: accessed-variable=PPort_54_1.DE1
            access OUT_PPort_54_2_DE1: accessed-variable=PPort_54_2.DE1
          read-local-variables:
            access RV_IRV55: accessed-variable=IRV55
          written-local-variables:
            access WV_IRV56: accessed-variable=IRV56
        Runnable55
          data-write-access:
            access OUT_PPort_55_1_DE1: accessed-variable=PPort_55_1.DE1
            access OUT_PPort_55_2_DE1: accessed-variable=PPort_55_2.DE1
          read-local-variables:
            access RV_IRV56: accessed-variable=IRV56
          written-local-variables:
            access WV_IRV57: accessed-variable=IRV57
        Runnable53
          data-write-access:
            access OUT_PPort_53_1_DE1: accessed-variable=PPort_53_1.DE1
            access OUT_PPort_53_2_DE1: accessed-variable=PPort_53_2.DE1
          read-local-variables:
            access RV_IRV54: accessed-variable=IRV54
          written-local-variables:
            access WV_IRV55: accessed-variable=IRV55
        Runnable52
          data-write-access:
            access OUT_PPort_52_1_DE1: accessed-variable=PPort_52_1.DE1
            access OUT_PPort_52_2_DE1: accessed-variable=PPort_52_2.DE1
          read-local-variables:
            access RV_IRV53: accessed-variable=IRV53
          written-local-variables:
            access WV_IRV54: accessed-variable=IRV54
        Runnable51
          data-write-access:
            access OUT_PPort_51_1_DE1: accessed-variable=PPort_51_1.DE1
            access OUT_PPort_51_2_DE1: accessed-variable=PPort_51_2.DE1
          read-local-variables:
            access RV_IRV52: accessed-variable=IRV52
          written-local-variables:
            access WV_IRV53: accessed-variable=IRV53
        Runnable50
          data-write-access:
            access OUT_PPort_50_1_DE1: accessed-variable=PPort_50_1.DE1
            access OUT_PPort_50_2_DE1: accessed-variable=PPort_50_2.DE1
          read-local-variables:
            access RV_IRV51: accessed-variable=IRV51
          written-local-variables:
            access WV_IRV52: accessed-variable=IRV52
        Runnable49
          data-write-access:
            access OUT_PPort_49_1_DE1: accessed-variable=PPort_49_1.DE1
            access OUT_PPort_49_2_DE1: accessed-variable=PPort_49_2.DE1
          read-local-variables:
            access RV_IRV50: accessed-variable=IRV50
          written-local-variables:
            access WV_IRV51: accessed-variable=IRV51
        Runnable48
          data-write-access:
            access OUT_PPort_48_1_DE1: accessed-variable=PPort_48_1.DE1
            access OUT_PPort_48_2_DE1: accessed-variable=PPort_48_2.DE1
          read-local-variables:
            access RV_IRV49: accessed-variable=IRV49
          written-local-variables:
            access WV_IRV50: accessed-variable=IRV50
        Runnable47
          data-write-access:
            access OUT_PPort_47_1_DE1: accessed-variable=PPort_47_1.DE1
            access OUT_PPort_47_2_DE1: accessed-variable=PPort_47_2.DE1
          read-local-variables:
            access RV_IRV48: accessed-variable=IRV48
          written-local-variables:
            access WV_IRV49: accessed-variable=IRV49
        Runnable46
          data-write-access:
            access OUT_PPort_46_1_DE1: accessed-variable=PPort_46_1.DE1
            access OUT_PPort_46_2_DE1: accessed-variable=PPort_46_2.DE1
          read-local-variables:
            access RV_IRV47: accessed-variable=IRV47
          written-local-variables:
            access WV_IRV48: accessed-variable=IRV48
        Runnable45
          data-write-access:
            access OUT_PPort_45_1_DE1: accessed-variable=PPort_45_1.DE1
            access OUT_PPort_45_2_DE1: accessed-variable=PPort_45_2.DE1
          read-local-variables:
            access RV_IRV46: accessed-variable=IRV46
          written-local-variables:
            access WV_IRV47: accessed-variable=IRV47
        Runnable44
          data-write-access:
            access OUT_PPort_44_1_DE1: accessed-variable=PPort_44_1.DE1
            access OUT_PPort_44_2_DE1: accessed-variable=PPort_44_2.DE1
          read-local-variables:
            access RV_IRV45: accessed-variable=IRV45
          written-local-variables:
            access WV_IRV46: accessed-variable=IRV46
        Runnable43
          data-write-access:
            access OUT_PPort_43_1_DE1: accessed-variable=PPort_43_1.DE1
            access OUT_PPort_43_2_DE1: accessed-variable=PPort_43_2.DE1
          read-local-variables:
            access RV_IRV44: accessed-variable=IRV44
          written-local-variables:
            access WV_IRV45: accessed-variable=IRV45
        Runnable42
          data-write-access:
            access OUT_PPort_42_1_DE1: accessed-variable=PPort_42_1.DE1
            access OUT_PPort_42_2_DE1: accessed-variable=PPort_42_2.DE1
          read-local-variables:
            access RV_IRV43: accessed-variable=IRV43
          written-local-variables:
            access WV_IRV44: accessed-variable=IRV44
        Runnable41
          data-write-access:
            access OUT_PPort_41_1_DE1: accessed-variable=PPort_41_1.DE1
            access OUT_PPort_41_2_DE1: accessed-variable=PPort_41_2.DE1
          read-local-variables:
            access RV_IRV42: accessed-variable=IRV42
          written-local-variables:
            access WV_IRV43: accessed-variable=IRV43
        Runnable40
          data-write-access:
            access OUT_PPort_40_1_DE1: accessed-variable=PPort_40_1.DE1
            access OUT_PPort_40_2_DE1: accessed-variable=PPort_40_2.DE1
          read-local-variables:
            access RV_IRV41: accessed-variable=IRV41
          written-local-variables:
            access WV_IRV42: accessed-variable=IRV42
        Runnable39
          data-write-access:
            access OUT_PPort_39_1_DE1: accessed-variable=PPort_39_1.DE1
            access OUT_PPort_39_2_DE1: accessed-variable=PPort_39_2.DE1
          read-local-variables:
            access RV_IRV40: accessed-variable=IRV40
          written-local-variables:
            access WV_IRV41: accessed-variable=IRV41
        Runnable38
          data-write-access:
            access OUT_PPort_38_1_DE1: accessed-variable=PPort_38_1.DE1
            access OUT_PPort_38_2_DE1: accessed-variable=PPort_38_2.DE1
          read-local-variables:
            access RV_IRV39: accessed-variable=IRV39
          written-local-variables:
            access WV_IRV40: accessed-variable=IRV40
        Runnable37
          data-write-access:
            access OUT_PPort_37_1_DE1: accessed-variable=PPort_37_1.DE1
            access OUT_PPort_37_2_DE1: accessed-variable=PPort_37_2.DE1
          read-local-variables:
            access RV_IRV38: accessed-variable=IRV38
          written-local-variables:
            access WV_IRV39: accessed-variable=IRV39
        Runnable36
          data-write-access:
            access OUT_PPort_36_1_DE1: accessed-variable=PPort_36_1.DE1
            access OUT_PPort_36_2_DE1: accessed-variable=PPort_36_2.DE1
          read-local-variables:
            access RV_IRV37: accessed-variable=IRV37
          written-local-variables:
            access WV_IRV38: accessed-variable=IRV38
        Runnable35
          data-write-access:
            access OUT_PPort_35_1_DE1: accessed-variable=PPort_35_1.DE1
            access OUT_PPort_35_2_DE1: accessed-variable=PPort_35_2.DE1
          read-local-variables:
            access RV_IRV36: accessed-variable=IRV36
          written-local-variables:
            access WV_IRV37: accessed-variable=IRV37
        Runnable34
          data-write-access:
            access OUT_PPort_34_1_DE1: accessed-variable=PPort_34_1.DE1
            access OUT_PPort_34_2_DE1: accessed-variable=PPort_34_2.DE1
          read-local-variables:
            access RV_IRV35: accessed-variable=IRV35
          written-local-variables:
            access WV_IRV36: accessed-variable=IRV36
        Runnable32
          data-write-access:
            access OUT_PPort_32_1_DE1: accessed-variable=PPort_32_1.DE1
            access OUT_PPort_32_2_DE1: accessed-variable=PPort_32_2.DE1
          read-local-variables:
            access RV_IRV33: accessed-variable=IRV33
          written-local-variables:
            access WV_IRV34: accessed-variable=IRV34
        Runnable31
          data-write-access:
            access OUT_PPort_31_1_DE1: accessed-variable=PPort_31_1.DE1
            access OUT_PPort_31_2_DE1: accessed-variable=PPort_31_2.DE1
          read-local-variables:
            access RV_IRV32: accessed-variable=IRV32
          written-local-variables:
            access WV_IRV33: accessed-variable=IRV33
        Runnable30
          data-write-access:
            access OUT_PPort_30_1_DE1: accessed-variable=PPort_30_1.DE1
            access OUT_PPort_30_2_DE1: accessed-variable=PPort_30_2.DE1
          read-local-variables:
            access RV_IRV31: accessed-variable=IRV31
          written-local-variables:
            access WV_IRV32: accessed-variable=IRV32
        Runnable29
          data-write-access:
            access OUT_PPort_29_1_DE1: accessed-variable=PPort_29_1.DE1
            access OUT_PPort_29_2_DE1: accessed-variable=PPort_29_2.DE1
          read-local-variables:
            access RV_IRV30: accessed-variable=IRV30
          written-local-variables:
            access WV_IRV31: accessed-variable=IRV31
        Runnable28
          data-write-access:
            access OUT_PPort_28_1_DE1: accessed-variable=PPort_28_1.DE1
            access OUT_PPort_28_2_DE1: accessed-variable=PPort_28_2.DE1
          read-local-variables:
            access RV_IRV29: accessed-variable=IRV29
          written-local-variables:
            access WV_IRV30: accessed-variable=IRV30
        Runnable27
          data-write-access:
            access OUT_PPort_27_1_DE1: accessed-variable=PPort_27_1.DE1
            access OUT_PPort_27_2_DE1: accessed-variable=PPort_27_2.DE1
          read-local-variables:
            access RV_IRV28: accessed-variable=IRV28
          written-local-variables:
            access WV_IRV29: accessed-variable=IRV29
        Runnable26
          data-write-access:
            access OUT_PPort_26_1_DE1: accessed-variable=PPort_26_1.DE1
            access OUT_PPort_26_2_DE1: accessed-variable=PPort_26_2.DE1
          read-local-variables:
            access RV_IRV27: accessed-variable=IRV27
          written-local-variables:
            access WV_IRV28: accessed-variable=IRV28
        Runnable24
          data-write-access:
            access OUT_PPort_24_1_DE1: accessed-variable=PPort_24_1.DE1
            access OUT_PPort_24_2_DE1: accessed-variable=PPort_24_2.DE1
          read-local-variables:
            access RV_IRV25: accessed-variable=IRV25
          written-local-variables:
            access WV_IRV26: accessed-variable=IRV26
        Runnable25
          data-write-access:
            access OUT_PPort_25_1_DE1: accessed-variable=PPort_25_1.DE1
            access OUT_PPort_25_2_DE1: accessed-variable=PPort_25_2.DE1
          read-local-variables:
            access RV_IRV26: accessed-variable=IRV26
          written-local-variables:
            access WV_IRV27: accessed-variable=IRV27
        Runnable23
          data-write-access:
            access OUT_PPort_23_1_DE1: accessed-variable=PPort_23_1.DE1
            access OUT_PPort_23_2_DE1: accessed-variable=PPort_23_2.DE1
          read-local-variables:
            access RV_IRV24: accessed-variable=IRV24
          written-local-variables:
            access WV_IRV25: accessed-variable=IRV25
        Runnable22
          data-write-access:
            access OUT_PPort_22_1_DE1: accessed-variable=PPort_22_1.DE1
            access OUT_PPort_22_2_DE1: accessed-variable=PPort_22_2.DE1
          read-local-variables:
            access RV_IRV23: accessed-variable=IRV23
          written-local-variables:
            access WV_IRV24: accessed-variable=IRV24
        Runnable21
          data-write-access:
            access OUT_PPort_21_1_DE1: accessed-variable=PPort_21_1.DE1
            access OUT_PPort_21_2_DE1: accessed-variable=PPort_21_2.DE1
          read-local-variables:
            access RV_IRV22: accessed-variable=IRV22
          written-local-variables:
            access WV_IRV23: accessed-variable=IRV23
        Runnable20
          data-write-access:
            access OUT_PPort_20_1_DE1: accessed-variable=PPort_20_1.DE1
            access OUT_PPort_20_2_DE1: accessed-variable=PPort_20_2.DE1
          read-local-variables:
            access RV_IRV21: accessed-variable=IRV21
          written-local-variables:
            access WV_IRV22: accessed-variable=IRV22
        Runnable19
          data-write-access:
            access OUT_PPort_19_1_DE1: accessed-variable=PPort_19_1.DE1
            access OUT_PPort_19_2_DE1: accessed-variable=PPort_19_2.DE1
          read-local-variables:
            access RV_IRV20: accessed-variable=IRV20
          written-local-variables:
            access WV_IRV21: accessed-variable=IRV21
        Runnable18
          data-write-access:
            access OUT_PPort_18_1_DE1: accessed-variable=PPort_18_1.DE1
            access OUT_PPort_18_2_DE1: accessed-variable=PPort_18_2.DE1
          read-local-variables:
            access RV_IRV19: accessed-variable=IRV19
          written-local-variables:
            access WV_IRV20: accessed-variable=IRV20
        Runnable17
          data-write-access:
            access OUT_PPort_17_1_DE1: accessed-variable=PPort_17_1.DE1
            access OUT_PPort_17_2_DE1: accessed-variable=PPort_17_2.DE1
          read-local-variables:
            access RV_IRV18: accessed-variable=IRV18
          written-local-variables:
            access WV_IRV19: accessed-variable=IRV19
        Runnable16
          data-write-access:
            access OUT_PPort_16_1_DE1: accessed-variable=PPort_16_1.DE1
            access OUT_PPort_16_2_DE1: accessed-variable=PPort_16_2.DE1
          read-local-variables:
            access RV_IRV17: accessed-variable=IRV17
          written-local-variables:
            access WV_IRV18: accessed-variable=IRV18
        Runnable15
          data-write-access:
            access OUT_PPort_15_1_DE1: accessed-variable=PPort_15_1.DE1
            access OUT_PPort_15_2_DE1: accessed-variable=PPort_15_2.DE1
          read-local-variables:
            access RV_IRV16: accessed-variable=IRV16
          written-local-variables:
            access WV_IRV17: accessed-variable=IRV17
        Runnable14
          data-write-access:
            access OUT_PPort_14_1_DE1: accessed-variable=PPort_14_1.DE1
            access OUT_PPort_14_2_DE1: accessed-variable=PPort_14_2.DE1
          read-local-variables:
            access RV_IRV15: accessed-variable=IRV15
          written-local-variables:
            access WV_IRV16: accessed-variable=IRV16
        Runnable11
          data-write-access:
            access OUT_PPort_11_1_DE1: accessed-variable=PPort_11_1.DE1
            access OUT_PPort_11_2_DE1: accessed-variable=PPort_11_2.DE1
          read-local-variables:
            access RV_IRV12: accessed-variable=IRV12
          written-local-variables:
            access WV_IRV13: accessed-variable=IRV13
        Runnable12
          data-write-access:
            access OUT_PPort_12_1_DE1: accessed-variable=PPort_12_1.DE1
            access OUT_PPort_12_2_DE1: accessed-variable=PPort_12_2.DE1
          read-local-variables:
            access RV_IRV13: accessed-variable=IRV13
          written-local-variables:
            access WV_IRV14: accessed-variable=IRV14
        Runnable10
          data-write-access:
            access OUT_PPort_10_1_DE1: accessed-variable=PPort_10_1.DE1
            access OUT_PPort_10_2_DE1: accessed-variable=PPort_10_2.DE1
          read-local-variables:
            access RV_IRV11: accessed-variable=IRV11
          written-local-variables:
            access WV_IRV12: accessed-variable=IRV12
        Runnable9
          data-write-access:
            access OUT_PPort_9_1_DE1: accessed-variable=PPort_9_1.DE1
            access OUT_PPort_9_2_DE1: accessed-variable=PPort_9_2.DE1
          read-local-variables:
            access RV_IRV10: accessed-variable=IRV10
          written-local-variables:
            access WV_IRV11: accessed-variable=IRV11
        Runnable8
          data-write-access:
            access OUT_PPort_8_1_DE1: accessed-variable=PPort_8_1.DE1
            access OUT_PPort_8_2_DE1: accessed-variable=PPort_8_2.DE1
          read-local-variables:
            access RV_IRV9: accessed-variable=IRV9
          written-local-variables:
            access WV_IRV10: accessed-variable=IRV10
        Runnable7
          data-write-access:
            access OUT_PPort_7_1_DE1: accessed-variable=PPort_7_1.DE1
            access OUT_PPort_7_2_DE1: accessed-variable=PPort_7_2.DE1
          read-local-variables:
            access RV_IRV8: accessed-variable=IRV8
          written-local-variables:
            access WV_IRV9: accessed-variable=IRV9
        Runnable6
          data-write-access:
            access OUT_PPort_6_1_DE1: accessed-variable=PPort_6_1.DE1
            access OUT_PPort_6_2_DE1: accessed-variable=PPort_6_2.DE1
          read-local-variables:
            access RV_IRV7: accessed-variable=IRV7
          written-local-variables:
            access WV_IRV8: accessed-variable=IRV8
        Runnable5
          data-write-access:
            access OUT_PPort_5_1_DE1: accessed-variable=PPort_5_1.DE1
            access OUT_PPort_5_2_DE1: accessed-variable=PPort_5_2.DE1
          read-local-variables:
            access RV_IRV6: accessed-variable=IRV6
          written-local-variables:
            access WV_IRV7: accessed-variable=IRV7
        Runnable13
          data-write-access:
            access OUT_PPort_13_1_DE1: accessed-variable=PPort_13_1.DE1
            access OUT_PPort_13_2_DE1: accessed-variable=PPort_13_2.DE1
          read-local-variables:
            access RV_IRV14: accessed-variable=IRV14
          written-local-variables:
            access WV_IRV15: accessed-variable=IRV15
        Runnable33
          data-write-access:
            access OUT_PPort_33_1_DE1: accessed-variable=PPort_33_1.DE1
            access OUT_PPort_33_2_DE1: accessed-variable=PPort_33_2.DE1
          read-local-variables:
            access RV_IRV34: accessed-variable=IRV34
          written-local-variables:
            access WV_IRV35: accessed-variable=IRV35
        Runnable56
          data-write-access:
            access OUT_PPort_56_1_DE1: accessed-variable=PPort_56_1.DE1
            access OUT_PPort_56_2_DE1: accessed-variable=PPort_56_2.DE1
          read-local-variables:
            access RV_IRV57: accessed-variable=IRV57
          written-local-variables:
            access WV_IRV58: accessed-variable=IRV58
        Runnable70
          data-write-access:
            access OUT_PPort_70_1_DE1: accessed-variable=PPort_70_1.DE1
            access OUT_PPort_70_2_DE1: accessed-variable=PPort_70_2.DE1
          read-local-variables:
            access RV_IRV71: accessed-variable=IRV71
          written-local-variables:
            access WV_IRV72: accessed-variable=IRV72
        Runnable86
          data-write-access:
            access OUT_PPort_86_1_DE1: accessed-variable=PPort_86_1.DE1
            access OUT_PPort_86_2_DE1: accessed-variable=PPort_86_2.DE1
          read-local-variables:
            access RV_IRV87: accessed-variable=IRV87
          written-local-variables:
            access WV_IRV88: accessed-variable=IRV88
package /pkg/if
  sender receiver interface Interface1
    data DE1: category=VALUE, sw-calibration-access=READ-ONLY, type=Double
    data DE2: category=ARRAY, sw-calibration-access=READ-ONLY, type=rt_Array_Double_2
  sender receiver interface Interface2
    4 x data, all with sw-calibration-access=READ-ONLY:
      DE1: category=VALUE, type=SInt8
      DE2: category=VALUE, type=SInt8
      DE3: category=ARRAY, type=rt_Array_SInt8_2
      DE4: category=VALUE, type=Double
package /pkg/dt
  impl type rt_Array_Double_2: category=ARRAY
    element rt_Array_Double_2: array-size=2, array-size-semantics=FIXED-SIZE, implementation-data-type=Double
  impl type rt_Array_SInt8_2: category=ARRAY
    element rt_Array_SInt8_2: array-size=2, array-size-semantics=FIXED-SIZE, implementation-data-type=SInt8
package /pkg/dt/Ground
  4 x constant specification:
    DefaultInitValue_Double: value-spec=0
    DefaultInitValu_036fab392deee624: value-spec=[{short-label=DefaultInitValu_d172891e92bde674, constant=DefaultInitValue_Double}, {short-label=DefaultInitValu_2d898f9704c2f030, constant=DefaultInitValue_Double}]
    DefaultInitValue_SInt8: value-spec=0
    DefaultInitValu_33c01c7d02936bc6: value-spec=[{short-label=DefaultInitValu_ea84cfedb01feb42, constant=DefaultInitValue_SInt8}, {short-label=DefaultInitValu_5f83b4901e9f9ad9, constant=DefaultInitValue_SInt8}]
package /pkg/imp
  swc implementation ASWC_impl: programming-language=C, sw-version=4.148.1, used-code-generator=Embedded Coder 7.6 (R2021a) 14-Nov-2020, vendor-id=0, behavior=IB
    code-descriptors:
      code Code
        artifact-descriptors:
          short-label=large_scale_autosar_swc_expfcns_c, category=SWSRC
          short-label=large_scale_autosar_swc_expfcns_h, category=SWHDR
          short-label=rtwtypes_h, category=SWHDR
    resource consumption RsrcCons_large_scale_autosar_swc_expfcns
package /Timing
  swc timing ASWC_timing: behavior=IB
    timing-requirements:
      execution order constraint EOC
        ordered-elements:
          108 x eoc executable entity ref:
            Runnable1: executable=Runnable1, successor=Runnable2
            Runnable2: executable=Runnable2, successor=Runnable4
            Runnable4: executable=Runnable4, successor=Runnable5
            Runnable5: executable=Runnable5, successor=Runnable6
            Runnable6: executable=Runnable6, successor=Runnable7
            Runnable7: executable=Runnable7, successor=Runnable8
            Runnable8: executable=Runnable8, successor=Runnable9
            Runnable9: executable=Runnable9, successor=Runnable10
            Runnable10: executable=Runnable10, successor=Runnable11
            Runnable11: executable=Runnable11, successor=Runnable12
            Runnable12: executable=Runnable12, successor=Runnable13
            Runnable13: executable=Runnable13, successor=Runnable14
            Runnable14: executable=Runnable14, successor=Runnable15
            Runnable15: executable=Runnable15, successor=Runnable16
            Runnable16: executable=Runnable16, successor=Runnable17
            Runnable17: executable=Runnable17, successor=Runnable18
            Runnable18: executable=Runnable18, successor=Runnable19
            Runnable19: executable=Runnable19, successor=Runnable20
            Runnable20: executable=Runnable20, successor=Runnable21
            Runnable21: executable=Runnable21, successor=Runnable22
            Runnable22: executable=Runnable22, successor=Runnable23
            Runnable23: executable=Runnable23, successor=Runnable24
            Runnable24: executable=Runnable24, successor=Runnable25
            Runnable25: executable=Runnable25, successor=Runnable26
            Runnable26: executable=Runnable26, successor=Runnable27
            Runnable27: executable=Runnable27, successor=Runnable28
            Runnable28: executable=Runnable28, successor=Runnable29
            Runnable29: executable=Runnable29, successor=Runnable30
            Runnable30: executable=Runnable30, successor=Runnable31
            Runnable31: executable=Runnable31, successor=Runnable32
            Runnable32: executable=Runnable32, successor=Runnable33
            Runnable33: executable=Runnable33, successor=Runnable34
            Runnable34: executable=Runnable34, successor=Runnable35
            Runnable35: executable=Runnable35, successor=Runnable36
            Runnable36: executable=Runnable36, successor=Runnable37
            Runnable37: executable=Runnable37, successor=Runnable38
            Runnable38: executable=Runnable38, successor=Runnable39
            Runnable39: executable=Runnable39, successor=Runnable40
            Runnable40: executable=Runnable40, successor=Runnable41
            Runnable41: executable=Runnable41, successor=Runnable42
            Runnable42: executable=Runnable42, successor=Runnable43
            Runnable43: executable=Runnable43, successor=Runnable44
            Runnable44: executable=Runnable44, successor=Runnable45
            Runnable45: executable=Runnable45, successor=Runnable46
            Runnable46: executable=Runnable46, successor=Runnable47
            Runnable47: executable=Runnable47, successor=Runnable48
            Runnable48: executable=Runnable48, successor=Runnable49
            Runnable49: executable=Runnable49, successor=Runnable50
            Runnable50: executable=Runnable50, successor=Runnable51
            Runnable51: executable=Runnable51, successor=Runnable52
            Runnable52: executable=Runnable52, successor=Runnable53
            Runnable53: executable=Runnable53, successor=Runnable54
            Runnable54: executable=Runnable54, successor=Runnable55
            Runnable55: executable=Runnable55, successor=Runnable56
            Runnable56: executable=Runnable56, successor=Runnable57
            Runnable57: executable=Runnable57, successor=Runnable58
            Runnable58: executable=Runnable58, successor=Runnable59
            Runnable59: executable=Runnable59, successor=Runnable60
            Runnable60: executable=Runnable60, successor=Runnable61
            Runnable61: executable=Runnable61, successor=Runnable62
            Runnable62: executable=Runnable62, successor=Runnable63
            Runnable63: executable=Runnable63, successor=Runnable64
            Runnable64: executable=Runnable64, successor=Runnable65
            Runnable65: executable=Runnable65, successor=Runnable66
            Runnable66: executable=Runnable66, successor=Runnable67
            Runnable67: executable=Runnable67, successor=Runnable68
            Runnable68: executable=Runnable68, successor=Runnable69
            Runnable69: executable=Runnable69, successor=Runnable70
            Runnable70: executable=Runnable70, successor=Runnable71
            Runnable71: executable=Runnable71, successor=Runnable72
            Runnable72: executable=Runnable72, successor=Runnable73
            Runnable73: executable=Runnable73, successor=Runnable74
            Runnable74: executable=Runnable74, successor=Runnable75
            Runnable75: executable=Runnable75, successor=Runnable76
            Runnable76: executable=Runnable76, successor=Runnable77
            Runnable77: executable=Runnable77, successor=Runnable78
            Runnable78: executable=Runnable78, successor=Runnable79
            Runnable79: executable=Runnable79, successor=Runnable80
            Runnable80: executable=Runnable80, successor=Runnable81
            Runnable81: executable=Runnable81, successor=Runnable82
            Runnable82: executable=Runnable82, successor=Runnable83
            Runnable83: executable=Runnable83, successor=Runnable84
            Runnable84: executable=Runnable84, successor=Runnable85
            Runnable85: executable=Runnable85, successor=Runnable86
            Runnable86: executable=Runnable86, successor=Runnable87
            Runnable87: executable=Runnable87, successor=Runnable88
            Runnable88: executable=Runnable88, successor=Runnable89
            Runnable89: executable=Runnable89, successor=Runnable90
            Runnable90: executable=Runnable90, successor=Runnable91
            Runnable91: executable=Runnable91, successor=Runnable92
            Runnable92: executable=Runnable92, successor=Runnable93
            Runnable93: executable=Runnable93, successor=Runnable94
            Runnable94: executable=Runnable94, successor=Runnable95
            Runnable95: executable=Runnable95, successor=Runnable96
            Runnable96: executable=Runnable96, successor=Runnable97
            Runnable97: executable=Runnable97, successor=Runnable98
            Runnable98: executable=Runnable98, successor=Runnable99
            Runnable99: executable=Runnable99, successor=Runnable100
            Runnable100: executable=Runnable100, successor=Runnable101
            Runnable101: executable=Runnable101, successor=Runnable102
            Runnable102: executable=Runnable102, successor=Runnable103
            Runnable103: executable=Runnable103, successor=Runnable104
            Runnable104: executable=Runnable104, successor=Runnable105
            Runnable105: executable=Runnable105, successor=Runnable106
            Runnable106: executable=Runnable106, successor=Runnable107
            Runnable107: executable=Runnable107, successor=Runnable108
            Runnable108: executable=Runnable108, successor=Runnable3
            Runnable3: executable=Runnable3
